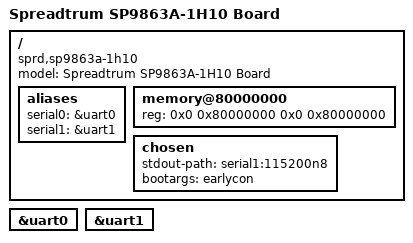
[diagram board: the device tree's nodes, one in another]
/* bench 9364.2.0 11eacf9f4e3b */
/* bench 9364.2.1 ea755cf59678 */
/* bench 9364.2.2 74bef8647382 */
/* bench 9364.2.3 f143ae1f0c97 */
/* bench 23599.0.0 a57ef30e2e31 */
/* bench 23599.0.1 0745289f3397 */
/* bench 23599.0.2 928cfe074a20 */
/* bench 23599.0.3 ba1071ea34d6 */
/* bench 23599.0.4 066b3f064c4a */
/* bench 23599.0.5 4db5ca83d925 */
/* bench 9364.2.7 4f43e3d4e529 */
/* bench 9364.2.8 3eb93251885b */
/* bench 9364.2.9 dab0ad6bbb2c */
/* bench 9364.2.10 b152bbb047da */
/* bench 9364.2.11 a0b5962cc9bf */
/* bench 9364.2.12 c8e314948db6 */
/*
 * Unisoc SP9863A-1h10 boards DTS file
 *
 * Copyright (C) 2019, Unisoc Inc.
 */

/dts-v1/;

#include "sc9863a.dtsi"

/ {
	model = "Spreadtrum SP9863A-1H10 Board";

	compatible = "sprd,sp9863a-1h10", "sprd,sc9863a";

	aliases {
		serial0 = &uart0;
		serial1 = &uart1;
	};

	memory@80000000 {
		device_type = "memory";
		reg = <0x0 0x80000000 0x0 0x80000000>;
	};

	chosen {
		stdout-path = "serial1:115200n8";
		bootargs = "earlycon";
	};
/* bench 6460.1.0 65a78a991e3d */
/* bench 6460.1.1 d862548dbc47 */
/* bench 6460.1.2 6a95faafb923 */
/* bench 6460.1.3 e23014911a00 */
/* bench 6460.1.4 911852e97256 */
/* bench 6460.1.5 0d637439253e */
};

&uart0 {
	status = "okay";
};

&uart1 {
	status = "okay";
};
